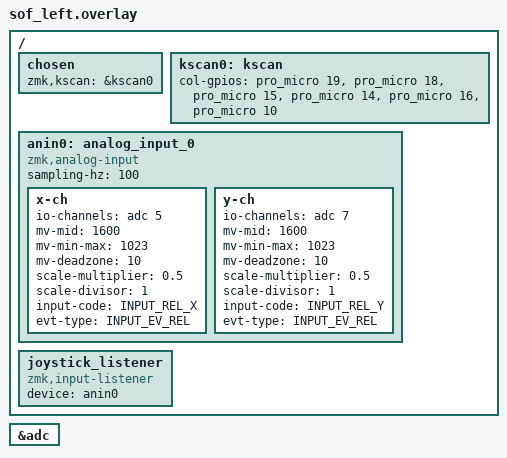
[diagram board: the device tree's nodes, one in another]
/*
 * Copyright (c) 2020 Ryan Cross
 *
 * SPDX-License-Identifier: MIT
 */

#include "sof.dtsi"
#include <zephyr/dt-bindings/input/input-event-codes.h>
/ {
    chosen {
        zmk,kscan = &kscan0;
    };
	kscan0: kscan {
    col-gpios
        = <&pro_micro 19 GPIO_ACTIVE_HIGH>
        , <&pro_micro 18 GPIO_ACTIVE_HIGH>
        , <&pro_micro 15 GPIO_ACTIVE_HIGH>
        , <&pro_micro 14 GPIO_ACTIVE_HIGH>
        , <&pro_micro 16 GPIO_ACTIVE_HIGH>
        , <&pro_micro 10 GPIO_ACTIVE_HIGH>
        ;
	};
};


&adc {
	status = "okay";
};

/ {
    anin0: analog_input_0 {
        compatible = "zmk,analog-input";
        sampling-hz = <100>;

        x-ch {
            io-channels = <&adc 5>;
            mv-mid = <1600>;
            mv-min-max = <1023>;
            mv-deadzone = <10>;               // 🔧 Very low
            scale-multiplier = <0.5>;
            scale-divisor = <1>;             // 🔧 Higher gain
            input-code = <INPUT_REL_X>;
            evt-type = <INPUT_EV_REL>;
        };

        y-ch {
            io-channels = <&adc 7>;
            mv-mid = <1600>;
            mv-min-max = <1023>;
            mv-deadzone = <10>;               // 🔧 Very low
            scale-multiplier = <0.5>;
            scale-divisor = <1>;
            input-code = <INPUT_REL_Y>;
            evt-type = <INPUT_EV_REL>;
        };
    };
};
/ {
    joystick_listener {
        compatible = "zmk,input-listener";
        device = <&anin0>;
    };
};
